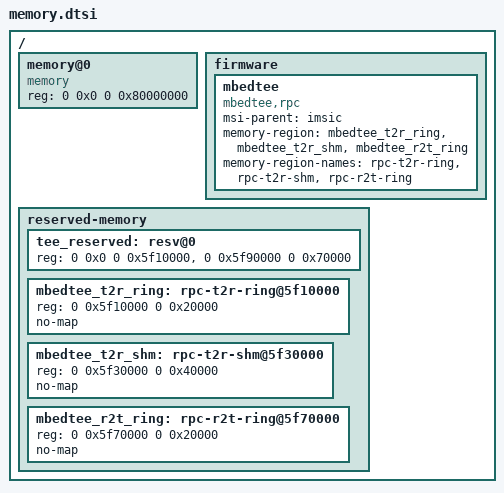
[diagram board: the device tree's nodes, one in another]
// SPDX-License-Identifier: Apache-2.0
/*
 * Copyright (c) 2025 Xing Loong <xing.xl.loong@gmail.com>
 */

/{
	#address-cells = <2>;
	#size-cells = <2>;

	memory@0 {
		compatible = "memory";
		device_type = "memory";

		reg = <0 0x0 0 0x80000000>;
	};

	firmware {
		mbedtee {
			compatible = "mbedtee,rpc";
			msi-parent = <&imsic>;

			/* shared memory regions (RISC-V IMSIC MSI) */
			memory-region = <&mbedtee_t2r_ring>, <&mbedtee_t2r_shm>,
							<&mbedtee_r2t_ring>;
			memory-region-names = "rpc-t2r-ring", "rpc-t2r-shm",
							"rpc-r2t-ring";
		};
	};

	reserved-memory {
		#address-cells = <2>;
		#size-cells = <2>;
		ranges;

		tee_reserved: resv@0 {
			reg = <0 0x0 0 0x5f10000>,
				<0 0x5f90000 0 0x70000>;
		};

		mbedtee_t2r_ring: rpc-t2r-ring@5f10000 {
			reg = <0 0x5f10000 0 0x20000>;
			no-map;
		};

		mbedtee_t2r_shm: rpc-t2r-shm@5f30000 {
			reg = <0 0x5f30000 0 0x40000>;
			no-map;
		};

		mbedtee_r2t_ring: rpc-r2t-ring@5f70000 {
			reg = <0 0x5f70000 0 0x20000>;
			no-map;
		};
	};
};
